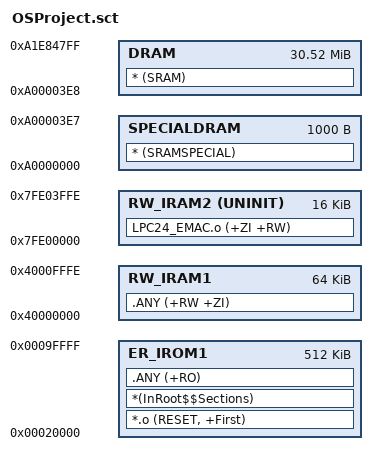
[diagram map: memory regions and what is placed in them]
; *************************************************************
; *** Scatter-Loading Description File generated by uVision ***
; *************************************************************
LR_IROM1 0x00020000 0x00080000  {    ; load region size_region            // Have BOOTLOAD //
  ER_IROM1 0x00020000 0x00080000  {  ; load address = execution address   // Have BOOTLOAD //
;
;LR_IROM1 0x00000000 0x00080000  {    ; load region size_region             // None BOOTLOAD SETTING //
;  ER_IROM1 0x00000000 0x00080000  {  ; load address = execution address    // None BOOTLOAD SETTING //

   *.o (RESET, +First)
   *(InRoot$$Sections)
   .ANY (+RO)
  }
  RW_IRAM1 0x40000000 0x0000FFFF  {  ; RW data
   .ANY (+RW +ZI)
  }
  RW_IRAM2 0x7FE00000 UNINIT 0x00003FFF  {  ; RW data
    LPC24_EMAC.o (+ZI +RW)
  }
  
  SPECIALDRAM   0XA0000000  0x000003E8
 {
   * (SRAMSPECIAL)
 }
  DRAM   0XA00003E8  0x01E84418
 {
   * (SRAM)
 }
 
  ;DRAM   0XA0000000  0x01E84800
 ;{
  ; * (SRAM)
 ;}
 
}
